AUTOSAR XML (schema 4-0-3)
package /MICROSAR_SWCS_DEV/Det_swc/ComponentTypes
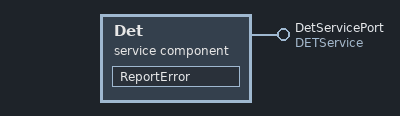
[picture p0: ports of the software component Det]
  service sw component type Det
    provide port DetServicePort: server-com-spec{operation=ReportError, queue-length=1}, provided-interface=DETService
    behavior DetInternalBehavior: port-api-option{enable-take-address=true, indirect-api=false, port-defined-argument-value{value=DetServicePort_0:4096, value-type=uint16}, port=DetServicePort}
      operation invoked event OpEventReportError_ReportError_DetServicePort: start-on-event=ReportError, operation=DetServicePort.ReportError
      runnable ReportError: can-be-invoked-concurrently=true, symbol=Det_ReportError
  swc implementation DetImplementation: behavior=DetInternalBehavior
    code-descriptors:
      code Default: artifact-descriptors=autosar-engineering-object={short-label=Default, category=SWSRC}
